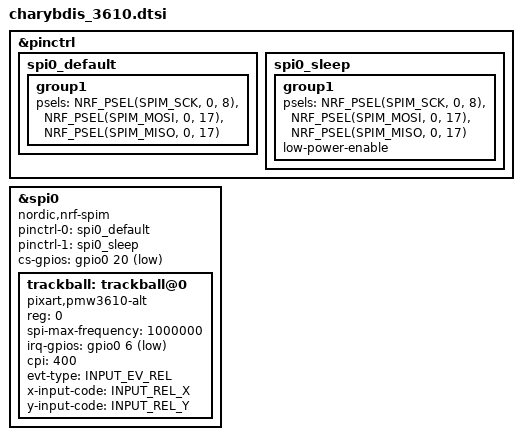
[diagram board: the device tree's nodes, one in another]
#include <zephyr/dt-bindings/input/input-event-codes.h>

&pinctrl {
    spi0_default: spi0_default {
        group1 {
            psels = <NRF_PSEL(SPIM_SCK, 0, 8)>,    // Pro Micro 0 (P0.08)
                    <NRF_PSEL(SPIM_MOSI, 0, 17)>,  // Pro Micro 2 (P0.17)
                    <NRF_PSEL(SPIM_MISO, 0, 17)>;  // Same as MOSI — PMW3610 3-wire SPI (SDIO)
        };
    };

    spi0_sleep: spi0_sleep {
        group1 {
            psels = <NRF_PSEL(SPIM_SCK, 0, 8)>,
                    <NRF_PSEL(SPIM_MOSI, 0, 17)>,
                    <NRF_PSEL(SPIM_MISO, 0, 17)>;
            low-power-enable;
        };
    };
};

&spi0 {
    status = "okay";
    compatible = "nordic,nrf-spim";
    pinctrl-0 = <&spi0_default>;
    pinctrl-1 = <&spi0_sleep>;
    pinctrl-names = "default", "sleep";
    cs-gpios = <&gpio0 20 GPIO_ACTIVE_LOW>; // Pro Micro 3 (P0.20) — not used by key matrix

    trackball: trackball@0 {
        status = "okay";
        compatible = "pixart,pmw3610-alt";
        reg = <0>;
        spi-max-frequency = <1000000>;
        irq-gpios = <&gpio0 6 (GPIO_ACTIVE_LOW | GPIO_PULL_UP)>; // Pro Micro 1 (P0.06) — not used by key matrix

        cpi = <400>;
        evt-type = <INPUT_EV_REL>;
        x-input-code = <INPUT_REL_X>;
        y-input-code = <INPUT_REL_Y>;
    };
};
